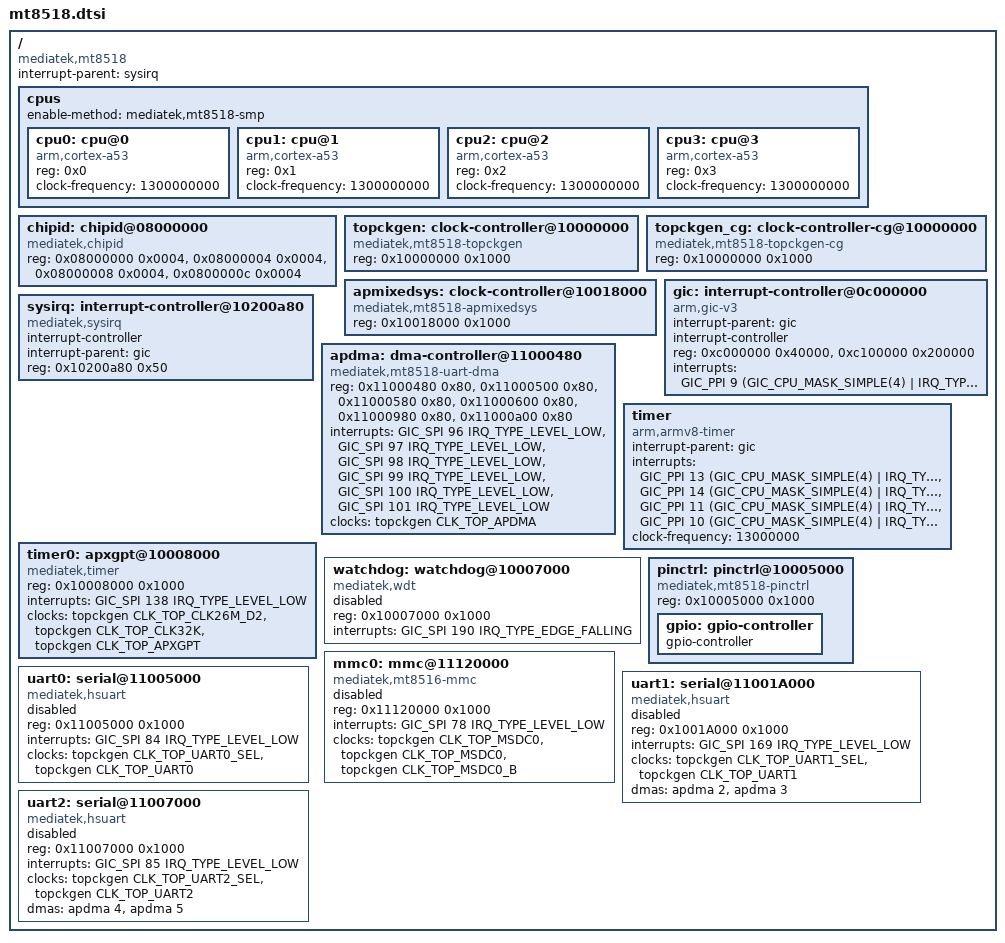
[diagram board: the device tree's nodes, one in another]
// SPDX-License-Identifier: (GPL-2.0 OR MIT)
/*
 * Copyright (C) 2019 MediaTek Inc.
 * Author: Mingming Lee <mingming.lee@mediatek.com>
 *
 */

#include <dt-bindings/clock/mt8518-clk.h>
#include <dt-bindings/gpio/gpio.h>
#include <dt-bindings/interrupt-controller/irq.h>
#include <dt-bindings/interrupt-controller/arm-gic.h>

/ {
	compatible = "mediatek,mt8518";
	interrupt-parent = <&sysirq>;
	#address-cells = <1>;
	#size-cells = <1>;

	cpus {
		#address-cells = <1>;
		#size-cells = <0>;
		enable-method = "mediatek,mt8518-smp";

		cpu0: cpu@0 {
			device_type = "cpu";
			compatible = "arm,cortex-a53";
			reg = <0x0>;
			clock-frequency = <1300000000>;
		};

		cpu1: cpu@1 {
			device_type = "cpu";
			compatible = "arm,cortex-a53";
			reg = <0x1>;
			clock-frequency = <1300000000>;
		};

		cpu2: cpu@2 {
			device_type = "cpu";
			compatible = "arm,cortex-a53";
			reg = <0x2>;
			clock-frequency = <1300000000>;
		};

		cpu3: cpu@3 {
			device_type = "cpu";
			compatible = "arm,cortex-a53";
			reg = <0x3>;
			clock-frequency = <1300000000>;
		};
	};

	chipid: chipid@08000000 {
		compatible = "mediatek,chipid";
		reg = <0x08000000 0x0004>,
		      <0x08000004 0x0004>,
		      <0x08000008 0x0004>,
		      <0x0800000c 0x0004>;
	};

	topckgen: clock-controller@10000000 {
		compatible = "mediatek,mt8518-topckgen";
		reg = <0x10000000 0x1000>;
		#clock-cells = <1>;
	};

	topckgen_cg: clock-controller-cg@10000000 {
		compatible = "mediatek,mt8518-topckgen-cg";
		reg = <0x10000000 0x1000>;
		#clock-cells = <1>;
	};

	apmixedsys: clock-controller@10018000 {
		compatible = "mediatek,mt8518-apmixedsys";
		reg = <0x10018000 0x1000>;
		#clock-cells = <1>;
	};

	gic: interrupt-controller@0c000000 {
		 compatible = "arm,gic-v3";
		#interrupt-cells = <3>;
		interrupt-parent = <&gic>;
		interrupt-controller;
		reg = <0xc000000 0x40000>,	/* GICD */
			  <0xc100000 0x200000>; /* GICR */
		interrupts = <GIC_PPI 9
			(GIC_CPU_MASK_SIMPLE(4) | IRQ_TYPE_LEVEL_HIGH)>;
	};

	sysirq: interrupt-controller@10200a80 {
		compatible = "mediatek,sysirq";
		interrupt-controller;
		#interrupt-cells = <3>;
		interrupt-parent = <&gic>;
		reg = <0x10200a80 0x50>;
	};

	apdma: dma-controller@11000480 {
		compatible = "mediatek,mt8518-uart-dma",
			"mediatek,mt6577-uart-dma";
		reg = <0x11000480 0x80>,
			  <0x11000500 0x80>,
			  <0x11000580 0x80>,
			  <0x11000600 0x80>,
			  <0x11000980 0x80>,
			  <0x11000a00 0x80>;
		interrupts = <GIC_SPI 96 IRQ_TYPE_LEVEL_LOW>,
			<GIC_SPI 97 IRQ_TYPE_LEVEL_LOW>,
			<GIC_SPI 98 IRQ_TYPE_LEVEL_LOW>,
			<GIC_SPI 99 IRQ_TYPE_LEVEL_LOW>,
			<GIC_SPI 100 IRQ_TYPE_LEVEL_LOW>,
			<GIC_SPI 101 IRQ_TYPE_LEVEL_LOW>;
		clocks = <&topckgen CLK_TOP_APDMA>;
		clock-names = "apdma";
		#dma-cells = <1>;
	};

	timer {
		compatible = "arm,armv8-timer";
		interrupt-parent = <&gic>;
		interrupts = <GIC_PPI 13
				 (GIC_CPU_MASK_SIMPLE(4) | IRQ_TYPE_LEVEL_LOW)>,
				 <GIC_PPI 14
				 (GIC_CPU_MASK_SIMPLE(4) | IRQ_TYPE_LEVEL_LOW)>,
				 <GIC_PPI 11
				 (GIC_CPU_MASK_SIMPLE(4) | IRQ_TYPE_LEVEL_LOW)>,
				 <GIC_PPI 10
				 (GIC_CPU_MASK_SIMPLE(4) | IRQ_TYPE_LEVEL_LOW)>;
		clock-frequency = <13000000>;
	};

	timer0: apxgpt@10008000 {
		compatible = "mediatek,timer",
			   "mediatek,mt8518-timer",
			   "mediatek,mt6577-timer";
		reg = <0x10008000 0x1000>;
		interrupts = <GIC_SPI 138 IRQ_TYPE_LEVEL_LOW>;
		clocks = <&topckgen CLK_TOP_CLK26M_D2>,
			 <&topckgen CLK_TOP_CLK32K>,
			 <&topckgen CLK_TOP_APXGPT>;
		clock-names = "clk13m",
			 "clk32k",
			 "bus";
	};

	watchdog: watchdog@10007000 {
		compatible = "mediatek,wdt";
		reg = <0x10007000 0x1000>;
		interrupts = <GIC_SPI 190 IRQ_TYPE_EDGE_FALLING>;
		#reset-cells = <1>;
		status = "disabled";
	};

	pinctrl: pinctrl@10005000 {
		compatible = "mediatek,mt8518-pinctrl";
		reg = <0x10005000 0x1000>;
		gpio: gpio-controller {
			gpio-controller;
			#gpio-cells = <2>;
		};
	};

	mmc0: mmc@11120000 {
		compatible = "mediatek,mt8516-mmc";
		reg = <0x11120000 0x1000>;
		interrupts = <GIC_SPI 78 IRQ_TYPE_LEVEL_LOW>;
		clocks = <&topckgen CLK_TOP_MSDC0>,
			<&topckgen CLK_TOP_MSDC0>,
			<&topckgen CLK_TOP_MSDC0_B>;
		clock-names = "source", "hclk", "source_cg";
		status = "disabled";
	};

	uart0: serial@11005000 {
		compatible = "mediatek,hsuart";
		reg = <0x11005000 0x1000>;
		interrupts = <GIC_SPI 84 IRQ_TYPE_LEVEL_LOW>;
		clocks = <&topckgen CLK_TOP_UART0_SEL>,
			<&topckgen CLK_TOP_UART0>;
		clock-names = "baud", "bus";
		status = "disabled";
	};

	uart1: serial@11001A000 {
		compatible = "mediatek,hsuart";
		reg = <0x1001A000 0x1000>;
		interrupts = <GIC_SPI 169 IRQ_TYPE_LEVEL_LOW>;
		clocks = <&topckgen CLK_TOP_UART1_SEL>,
			<&topckgen CLK_TOP_UART1>;
		clock-names = "baud", "bus";
		dmas = <&apdma 2
			&apdma 3>;
		dma-names = "tx", "rx";
		status = "disabled";
	};

	uart2: serial@11007000 {
		compatible = "mediatek,hsuart";
		reg = <0x11007000 0x1000>;
		interrupts = <GIC_SPI 85 IRQ_TYPE_LEVEL_LOW>;
		clocks = <&topckgen CLK_TOP_UART2_SEL>,
			<&topckgen CLK_TOP_UART2>;
		clock-names = "baud", "bus";
		dmas = <&apdma 4
			&apdma 5>;
		dma-names = "tx", "rx";
		status = "disabled";
	};

};
